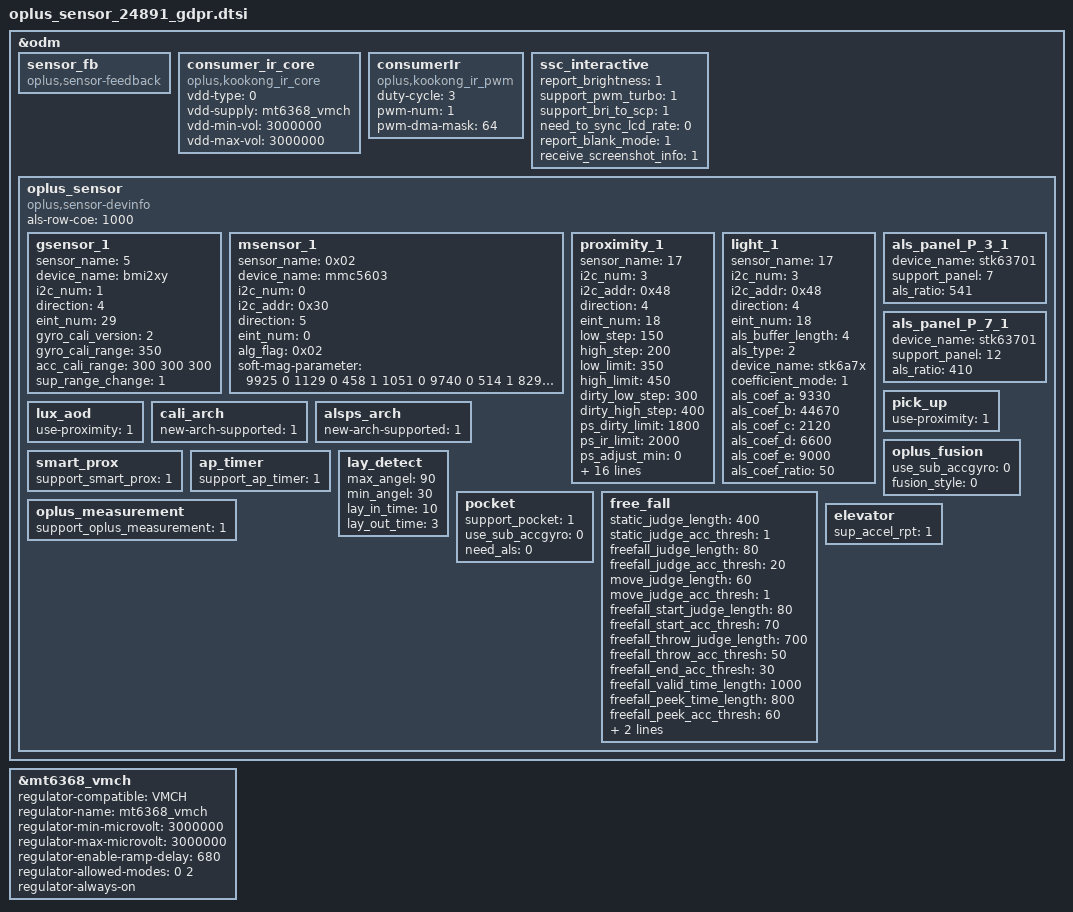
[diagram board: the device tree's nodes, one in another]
&odm {
	sensor_fb: sensor_fb {
		compatible = "oplus,sensor-feedback";
	};
	consumer_ir_core: consumer_ir_core {
		compatible = "oplus,kookong_ir_core";
		status = "okay";
		vdd-type = <0>;  /*0: internal LDO , 1: external LDO , 2: NO VDD */
		vdd-supply = <&mt6368_vmch>;
		vdd-min-vol = <3000000>;
		vdd-max-vol = <3000000>;
	};
	consumerIr: consumerIr {
		compatible = "oplus,kookong_ir_pwm";
		status = "okay";
		duty-cycle = <3>;
		pwm-num = <1>;
		pwm-dma-mask = <64>;
	};
	ssc_interactive: ssc_interactive {
		report_brightness = <1>;
		support_pwm_turbo = <1>;
		support_bri_to_scp = <1>;
		need_to_sync_lcd_rate = <0>;
		report_blank_mode = <1>;
		receive_screenshot_info = <1>;
	};
	oplus_sensor:oplus_sensor {
		compatible = "oplus,sensor-devinfo";
		als-row-coe = <1000>;
		/* sensor start */
		/*
			enum {
			LIS3DH,
			LSM6DS3,
			BMI160,
			LIS2HH12,
			LSM6DSM,
			BMI2XY,//5
			LSM6DSO,
			ICM4X6XX,
			ICM4263X,
			ICM4N607,
			BMI22X,
			SC7A20,
			MC34X9,
			BMA4XY,
			STK8329,
			BMI3XY,
			ICM456XY,//16
		};
		*/
		gsensor_1: gsensor_1 {
			status = "okay";
			sensor_name = <5>; // BMI2XY
			device_name = "bmi2xy";
			i2c_num = <1>;
			direction = <4>;
			eint_num = <29>;
			gyro_cali_version= <2>;
			gyro_cali_range =<350>;
			acc_cali_range= <300 300 300>;
			sup_range_change = <1>;
		};
		/*
		enum {
			AKM09911,
			MMC3530,
			MMC5603,
			MXG4300,
			AKM09918,
		};
		*/
		msensor_1: msensor_1 {
			status = "okay";
			sensor_name = <0x02>; // MMC5603
			device_name = "mmc5603";
			i2c_num = <0>;
			i2c_addr = <0x30>;
			direction = <5>;
			eint_num = <0>;
			alg_flag = <0x02>;
			soft-mag-parameter = <9925 0 1129 0 458 1 1051 0 9740 0 514 1 829 0 367 1 11233 0>;
		};

		proximity_1: proximity_1 {
			status = "okay";
			sensor_name = <17>; //stk63701
			i2c_num = <3>;
			i2c_addr = <0x48>;
			direction = <4>;
			eint_num = <18>;
			low_step = <150>;
			high_step = <200>;
			low_limit = <350>;
			high_limit = <450>;
			dirty_low_step = <300>;
			dirty_high_step = <400>;
			ps_dirty_limit = <1800>;
			ps_ir_limit = <2000>;
			ps_adjust_min = <0>;
			ps_adjust_max = <1850>;
			sampling_count = <5>;
			step_max = <400>;
			step_min = <80>;
			step_div = <2000>;
			anti_shake_delta = <70>;
			dynamic_cali_max = <2000>;
			raw2offset_radio = <1000>;
			offset_max = <60000>;
			offset_range_min = <0>;
			offset_range_max = <65534>;
			force_cali_limit = <2000>;
			cali_jitter_limit = <20>;
			cal_offset_margin = <3000>;
			parameter-number = <6>;
			sensor-reg = <0x05 0x20
					0x02 0x73
					0x03 0x3C>;
		};
		light_1: light_1 {
			status = "okay";
			sensor_name = <17>; //stk63701
			i2c_num = <3>;
			i2c_addr = <0x48>;
			direction = <4>;
			eint_num = <18>;
			als_buffer_length =<4>;
			als_type = <2>;//<1-normal;2-under screen;3-normal needed compensation>
			device_name = "stk6a7x";
			coefficient_mode = <1>;
			als_coef_a = <9330>; //*100
			als_coef_b = <44670>; //*100
			als_coef_c = <2120>; //*100
			als_coef_d = <6600>; //*100
			als_coef_e = <9000>; //*100
			als_coef_ratio = <50>;
		};
		als_panel_P_3_1: als_panel_P_3_1 {
			status = "okay";
			device_name = "stk63701";
			support_panel = <7>; // 1-SAMSUNG, 2-BOE, 3-TIANMA, 4-NT36672C, 5-HX83112F, 6-TM, 7-P_3, 8-P_B
			als_ratio = <541>;
		};
		als_panel_P_7_1: als_panel_P_7_1 {
			status = "okay";
			device_name = "stk63701";
			support_panel = <12>; // 1-SAMSUNG, 2-BOE, 3-TIANMA, 4-NT36672C, 5-HX83112F, 6-TM, 7-P_3, 8-P_B
			als_ratio = <410>;
		};
		pick_up: pick_up {
			status = "okay";
			use-proximity = <1>;
		};
		lux_aod: lux_aod {
			status = "okay";
			use-proximity = <1>;
		};
		cali_arch: cali_arch {
			status = "okay";
			new-arch-supported = <1>;
		};
		alsps_arch: alsps_arch {
			status = "okay";
			new-arch-supported = <1>;
		};
		oplus_fusion: oplus_fusion {
			status = "okay";
			use_sub_accgyro = <0>;
			fusion_style = <0>;
		};
		smart_prox: smart_prox {
			status = "okay";
			support_smart_prox = <1>;
		};
		ap_timer: ap_timer {
			status = "okay";
			support_ap_timer = <1>;
		};
		lay_detect: lay_detect{
			status = "okay";
			max_angel = <90>;
			min_angel = <30>;
			lay_in_time = <10>;
			lay_out_time = <3>;
		};
		pocket: pocket {
			status = "okay";
			support_pocket = <1>;
			use_sub_accgyro = <0>;
			need_als = <0>;
		};
		free_fall: free_fall{
			status = "okay";
			static_judge_length = <400>;
			static_judge_acc_thresh = <1>;
			freefall_judge_length = <80>;
			freefall_judge_acc_thresh = <20>;
			move_judge_length = <60>;
			move_judge_acc_thresh = <1>;
			freefall_start_judge_length  = <80>;
			freefall_start_acc_thresh = <70>;
			freefall_throw_judge_length = <700>;
			freefall_throw_acc_thresh = <50>;
			freefall_end_acc_thresh = <30>;
			freefall_valid_time_length = <1000>;
			freefall_peek_time_length = <800>;
			freefall_peek_acc_thresh = <60>;
			freefall_material_thresh = <900>;
			valid_peek_interval_thresh = <10000>;
		};
		oplus_measurement: oplus_measurement{
			status = "okay";
			support_oplus_measurement = <1>;
		};
		elevator: elevator{
			status = "okay";
			sup_accel_rpt = <1>;
		};
	};
/* sensor end */
};

&mt6368_vmch {
	regulator-compatible = "VMCH";
	regulator-name = "mt6368_vmch";
	regulator-min-microvolt = <3000000>;
	regulator-max-microvolt = <3000000>;
	regulator-enable-ramp-delay = <680>;
	regulator-allowed-modes = <0 2>;
	regulator-always-on;
};


